# STM32WB05 register map
File version: 1.0
Registers are 32-bit, read-write, reset 0x0 unless marked. A register's access mark holds for its fields unless they carry their own. Offsets are from the block's base; [hi:lo] are bit positions.

## RCC
Base 0x48400000
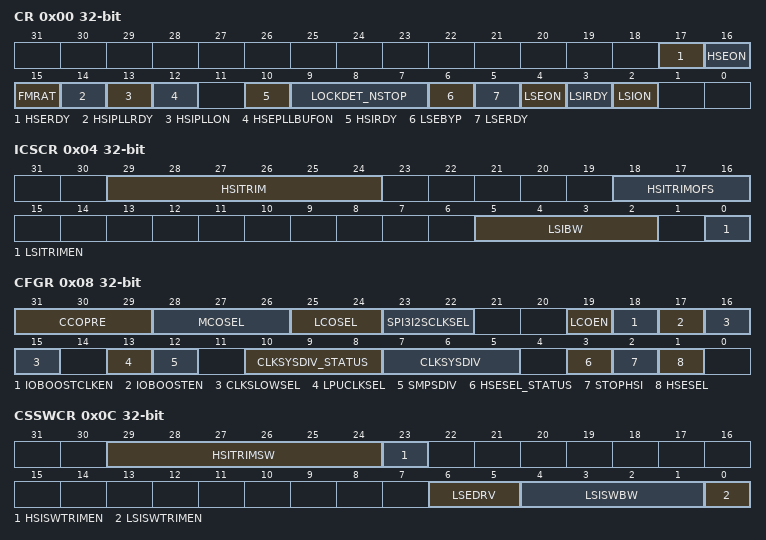
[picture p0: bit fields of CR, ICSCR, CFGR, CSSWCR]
0x00 CR
  [17] HSERDY
  [16] HSEON
    0=HSI (Enable HSI system clock); 1=HSE (Enable HSE system clock)
  [15] FMRAT
  [14] HSIPLLRDY
  [13] HSIPLLON
  [12] HSEPLLBUFON
  [10] HSIRDY
  [9:7] LOCKDET_NSTOP
  [6] LSEBYP
  [5] LSERDY
  [4] LSEON
  [3] LSIRDY
  [2] LSION
0x04 ICSCR
  [29:24] HSITRIM, [18:16] HSITRIMOFS, [5:2] LSIBW, [0] LSITRIMEN
0x08 CFGR
  [31:29] CCOPRE
  [28:26] MCOSEL
  [25:24] LCOSEL
    0=NOCLOCK (LSCO output disabled, no clock on LSCO); 2=LSI (LSI selection as LSCO source); 3=LSE (LSE selection as LSCO source)
  [23:22] SPI3I2SCLKSEL
    0=CLK16M (SPI3 I2S 16 MHz clock source selection bits); 1=CLK32M (SPI3 I2S 32 MHz clock source selection bits); 2=CLK64M (SPI3 I2S 64 MHz clock source selection bits)
  [19] LCOEN
  [18] IOBOOSTCLKEN
  [17] IOBOOSTEN
  [16:15] CLKSLOWSEL
    1=LSE (LSE selection for low speed clock); 2=LSI (Enable the LSI selection for low speed clock); 3=HSI64M_DIV2048 (HSI_64M divided by 2048 selection for low speed clock)
  [13] LPUCLKSEL
    0=CLK16M (LPUART Clock Selection 16 MHz); 1=CLKLSE (LPUART Clock Selection LSE source)
  [12] SMPSDIV
    0=DIV_2 (SMPS clock division 2 (SMPS clock is 8 MHz)); 1=DIV_4 (SMPS clock division 4 (SMPS clock is 4 MHz))
  [10:8] CLKSYSDIV_STATUS
  [7:5] CLKSYSDIV
    0=DIV_1 (RC64MPLL not divided as SYSCLK); 1=DIV_2 (RC64MPLL divided by 2 as SYSCLK); 2=DIV_4 (RC64MPLL divided by 4 as SYSCLK); 3=DIV_8 (RC64MPLL divided by 8 as SYSCLK); 4=DIV_16 (RC64MPLL divided by 16 as SYSCLK); 5=DIV_32 (RC64MPLL divided by 32 as SYSCLK); 6=DIV_64 (RC64MPLL divided by 64 as SYSCLK)
  [3] HSESEL_STATUS
  [2] STOPHSI
  [1] HSESEL
0x0C CSSWCR
  [29:24] HSITRIMSW
  [23] HSISWTRIMEN
  [6:5] LSEDRV
    0=LOW (Xtal mode lower driving capability); 1=MEDIUMLOW (Xtal mode medium low driving capability); 2=MEDIUMHIGH (Xtal mode medium high driving capability); 3=HIGH (Xtal mode higher driving capability)
  [4:1] LSISWBW
  [0] LSISWTRIMEN
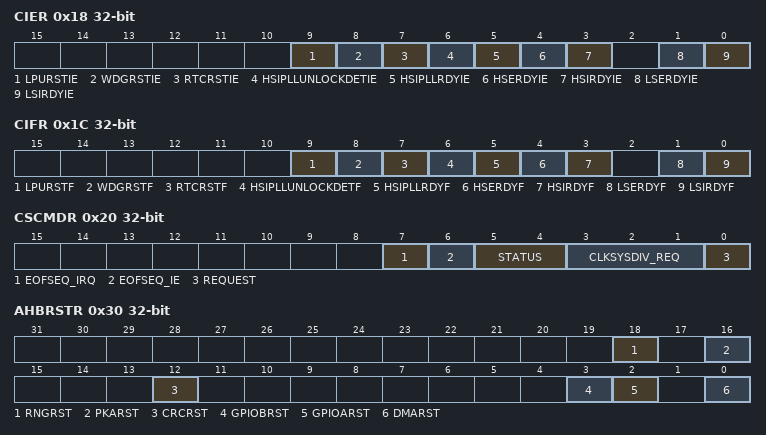
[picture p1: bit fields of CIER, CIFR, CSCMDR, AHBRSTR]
0x18 CIER
  [9] LPURSTIE, [8] WDGRSTIE, [7] RTCRSTIE, [6] HSIPLLUNLOCKDETIE, [5] HSIPLLRDYIE, [4] HSERDYIE, [3] HSIRDYIE, [1] LSERDYIE, [0] LSIRDYIE
0x1C CIFR
  [9] LPURSTF, [8] WDGRSTF, [7] RTCRSTF, [6] HSIPLLUNLOCKDETF, [5] HSIPLLRDYF, [4] HSERDYF, [3] HSIRDYF, [1] LSERDYF, [0] LSIRDYF
0x20 CSCMDR
  [7] EOFSEQ_IRQ
  [6] EOFSEQ_IE
  [5:4] STATUS
    0=IDLE (RC64MPLL Clock Switch Status IDLE); 1=ONGOING (RC64MPLL Clock Switch Status ONGOING); 2=DONE (RC64MPLL Clock Switch Status DONE)
  [3:1] CLKSYSDIV_REQ
    0=DIV_1 (RC64MPLL not divided as SYSCLK); 1=DIV_2 (RC64MPLL divided by 2 as SYSCLK); 2=DIV_4 (RC64MPLL divided by 4 as SYSCLK)
  [0] REQUEST
0x30 AHBRSTR
  [18] RNGRST, [16] PKARST, [12] CRCRST, [3] GPIOBRST, [2] GPIOARST, [0] DMARST
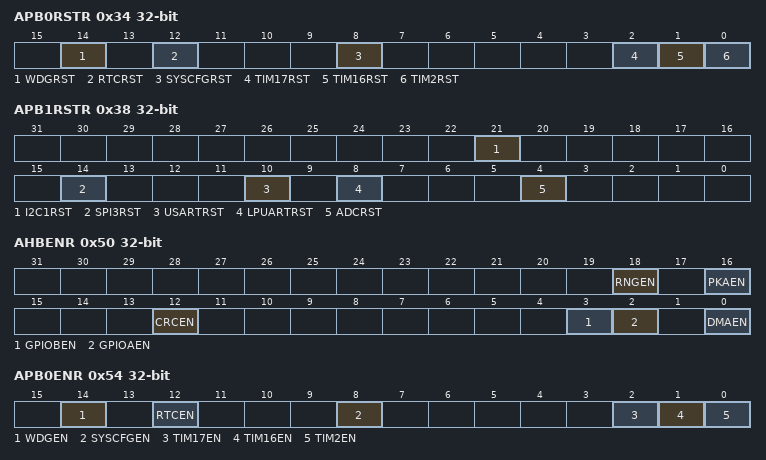
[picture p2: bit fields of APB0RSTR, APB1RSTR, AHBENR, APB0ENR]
0x34 APB0RSTR
  [14] WDGRST, [12] RTCRST, [8] SYSCFGRST, [2] TIM17RST, [1] TIM16RST, [0] TIM2RST
0x38 APB1RSTR
  [21] I2C1RST, [14] SPI3RST, [10] USARTRST, [8] LPUARTRST, [4] ADCRST
0x40 APB2RSTR
  [0] MRBLERST
0x50 AHBENR
  [18] RNGEN, [16] PKAEN, [12] CRCEN, [3] GPIOBEN, [2] GPIOAEN, [0] DMAEN
0x54 APB0ENR
  [14] WDGEN, [12] RTCEN, [8] SYSCFGEN, [2] TIM17EN, [1] TIM16EN, [0] TIM2EN
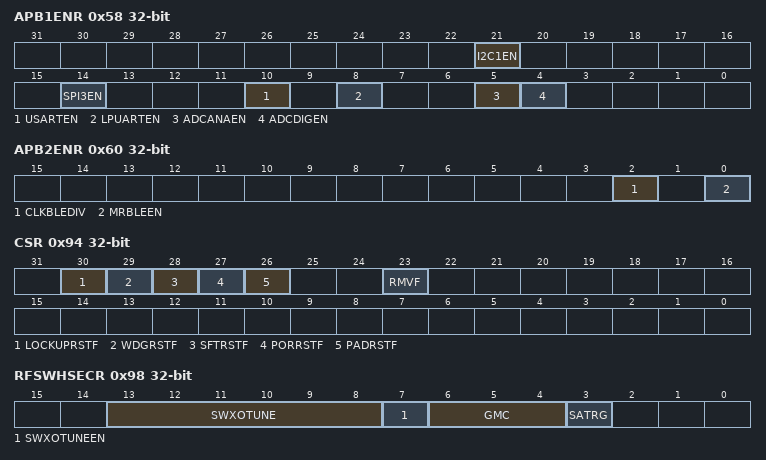
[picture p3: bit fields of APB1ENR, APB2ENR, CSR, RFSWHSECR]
0x58 APB1ENR
  [21] I2C1EN, [14] SPI3EN, [10] USARTEN, [8] LPUARTEN, [5] ADCANAEN, [4] ADCDIGEN
0x60 APB2ENR
  [2] CLKBLEDIV
    1=CLK_16M (Radio system clock 16 MHz); 0=CLK_32M (Radio system clock 32 MHz)
  [0] MRBLEEN
0x94 CSR
  [30] LOCKUPRSTF, [29] WDGRSTF, [28] SFTRSTF, [27] PORRSTF, [26] PADRSTF, [23] RMVF
0x98 RFSWHSECR
  [13:8] SWXOTUNE
  [7] SWXOTUNEEN
  [6:4] GMC
    0=CURRENTMAX_0 (HSE current control max limit = 0.18 mA/V); 1=CURRENTMAX_1 (HSE current control max limit = 0.57 mA/V); 2=CURRENTMAX_2 (HSE current control max limit = 0.78 mA/V); 3=CURRENTMAX_3 (HSE current control max limit = 1.13 mA/V); 4=CURRENTMAX_4 (HSE current control max limit = 0.61 mA/V); 5=CURRENTMAX_5 (HSE current control max limit = 1.65 mA/V); 6=CURRENTMAX_6 (HSE current control max limit = 2.12 mA/V); 7=CURRENTMAX_7 (HSE current control max limit = 2.84 mA/V)
  [3] SATRG
    0=HSEAMPTHRESHOLD_1_2 (HSE sense amplifier bias current factor = 1/2); 1=HSEAMPTHRESHOLD_3_4 (HSE sense amplifier bias current factor = 3/4)
0x9C RFHSECR
  [5:0] XOTUNE
